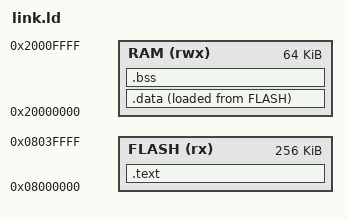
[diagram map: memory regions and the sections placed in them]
/* Cortex-M4 风格的链接脚本,让 .data/.bss 拥有真实 RAM 地址 */
MEMORY
{
  FLASH (rx)  : ORIGIN = 0x08000000, LENGTH = 256K
  RAM   (rwx) : ORIGIN = 0x20000000, LENGTH = 64K
}

ENTRY(main)

SECTIONS
{
  .text : {
    *(.text*)
    *(.rodata*)
  } > FLASH

  .data : {
    *(.data*)
  } > RAM AT > FLASH

  .bss : {
    *(.bss*)
    *(COMMON)
  } > RAM
}
